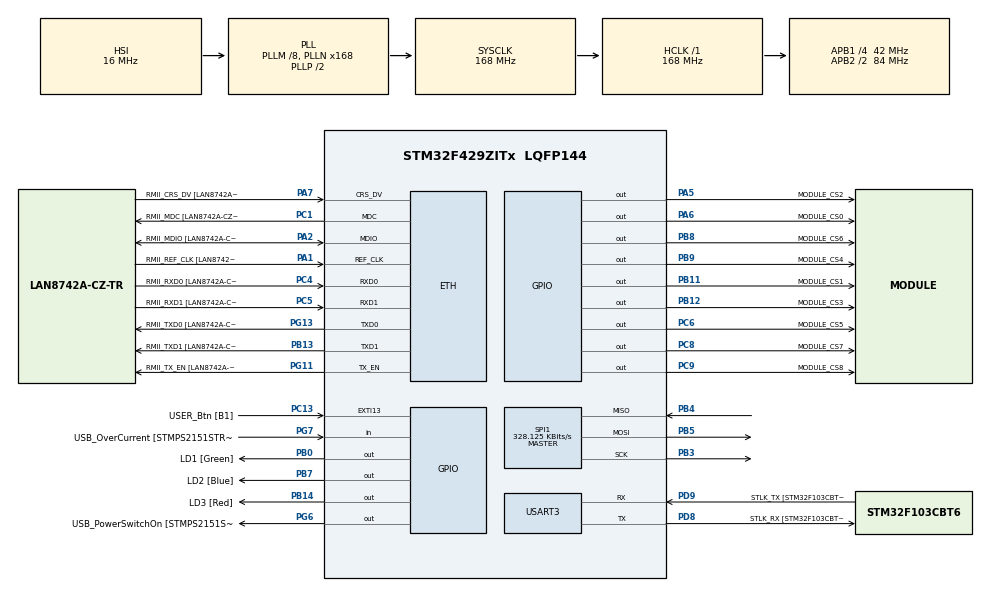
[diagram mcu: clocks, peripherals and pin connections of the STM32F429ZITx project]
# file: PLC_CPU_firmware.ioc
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Dma.Request0=SPI1_RX
Dma.Request1=SPI1_TX
Dma.SPI1_RX.0.Direction=DMA_PERIPH_TO_MEMORY
Dma.SPI1_RX.0.FIFOMode=DMA_FIFOMODE_DISABLE
Dma.SPI1_RX.0.Instance=DMA2_Stream0
Dma.SPI1_RX.0.MemDataAlignment=DMA_MDATAALIGN_BYTE
Dma.SPI1_RX.0.MemInc=DMA_MINC_ENABLE
Dma.SPI1_RX.0.Mode=DMA_NORMAL
Dma.SPI1_RX.0.PeriphDataAlignment=DMA_PDATAALIGN_BYTE
Dma.SPI1_RX.0.PeriphInc=DMA_PINC_DISABLE
Dma.SPI1_RX.0.Priority=DMA_PRIORITY_LOW
Dma.SPI1_TX.1.Direction=DMA_MEMORY_TO_PERIPH
Dma.SPI1_TX.1.FIFOMode=DMA_FIFOMODE_DISABLE
Dma.SPI1_TX.1.Instance=DMA2_Stream3
Dma.SPI1_TX.1.MemDataAlignment=DMA_MDATAALIGN_BYTE
Dma.SPI1_TX.1.MemInc=DMA_MINC_ENABLE
Dma.SPI1_TX.1.Mode=DMA_NORMAL
Dma.SPI1_TX.1.PeriphDataAlignment=DMA_PDATAALIGN_BYTE
Dma.SPI1_TX.1.PeriphInc=DMA_PINC_DISABLE
Dma.SPI1_TX.1.Priority=DMA_PRIORITY_LOW
ETH.MediaInterface=HAL_ETH_RMII_MODE
ETH.PHY_Name=LAN8742A_PHY_ADDRESS
ETH.PHY_Value=0
ETH.PhyAddress=0
FREERTOS.Events01=plc_status_flag,Static,plc_status_flagControlBlock
FREERTOS.Mutexes01=program_memory_write_mut,Static,program_memory_write_mut_cb
FREERTOS.Tasks01=DefaultTask,8,1024,DefaultTaskFcn,Default,NULL,Static,SystemInitTaskBuffer,SystemInitTaskControlBlock;TCPServerTask,16,1024,TCPServerTaskFcn,As weak,NULL,Static,TCPServerTaskBuffer,TCPServerTaskControlBlock;ModuleCtrlTask,55,1024,IoModuleControlTaskFcn,As external,NULL,Static,ModuleCtrlTaskBuffer,ModuleCtrlTaskControlBlock
FREERTOS.configCHECK_FOR_STACK_OVERFLOW=2
FREERTOS.configENABLE_FPU=0
FREERTOS.configMINIMAL_STACK_SIZE=1024
FREERTOS.configUSE_NEWLIB_REENTRANT=1
LWIP.BSP.number=1
LWIP.CHECKSUM_CHECK_IP=1
LWIP.CHECKSUM_CHECK_TCP=1
LWIP.CHECKSUM_GEN_IP=1
LWIP.CHECKSUM_GEN_TCP=1
LWIP.DEFAULT_THREAD_PRIO=46
LWIP.IP_ADDRESS=192.168.000.150
LWIP.LWIP_DHCP=0
LWIP.LWIP_NETIF_EXT_STATUS_CALLBACK=1
LWIP.LWIP_NETIF_STATUS_CALLBACK=1
LWIP.LWIP_STATS=0
LWIP.MEM_SIZE=16384
LWIP.NETMASK_ADDRESS=255.255.255.000
LWIP.TCPIP_THREAD_PRIO=47
LWIP.TCPIP_THREAD_STACKSIZE=2048
LWIP.Version=v2.1.2_Cube
LWIP0.BSP.STBoard=false
LWIP0.BSP.api=BSP_COMPONENT_DRIVER
LWIP0.BSP.component=LAN8742
LWIP0.BSP.instance=LAN8742
LWIP0.BSP.name=Driver_PHY
LWIP0.BSP.semaphore=S_LAN8742
LWIP0.BSP.solution=LAN8742
Mcu.Family=STM32F4
Mcu.Name=STM32F429ZITx
Mcu.Package=LQFP144
Mcu.UserConstants=hspi_module,$$_SPI1_IP_HANDLE_$$;htim_performance,$$_TIM5_IP_HANDLE_$$
NVIC.DMA2_Stream0_IRQn=true\:5\:0\:false\:false\:true\:true\:false\:true\:true
NVIC.DMA2_Stream3_IRQn=true\:5\:0\:false\:false\:true\:true\:false\:true\:true
NVIC.ETH_IRQn=true\:5\:0\:false\:false\:true\:true\:false\:true\:true
NVIC.PriorityGroup=NVIC_PRIORITYGROUP_4
NVIC.SPI1_IRQn=true\:5\:0\:false\:false\:true\:true\:true\:true\:true
NVIC.TIM7_IRQn=true\:15\:0\:false\:false\:true\:false\:false\:true\:true
NVIC.TimeBase=TIM7_IRQn
NVIC.TimeBaseIP=TIM7
PA1.GPIO_Label=RMII_REF_CLK [LAN8742A-CZ-TR_REFCLK0]
PA1.Mode=RMII
PA1.Signal=ETH_REF_CLK
PA10.GPIO_Label=USB_ID
PA10.Signal=USB_OTG_FS_ID
PA11.GPIO_Label=USB_DM
PA11.Signal=USB_OTG_FS_DM
PA12.GPIO_Label=USB_DP
PA12.Signal=USB_OTG_FS_DP
PA13.GPIO_Label=TMS
PA13.Mode=Serial_Wire
PA13.Signal=SYS_JTMS-SWDIO
PA14.GPIO_Label=TCK
PA14.Mode=Serial_Wire
PA14.Signal=SYS_JTCK-SWCLK
PA2.GPIO_Label=RMII_MDIO [LAN8742A-CZ-TR_MDIO]
PA2.Mode=RMII
PA2.Signal=ETH_MDIO
PA5.GPIO_Label=MODULE_CS2
PA5.Signal=GPIO_Output
PA6.GPIO_Label=MODULE_CS0
PA6.Signal=GPIO_Output
PA7.GPIO_Label=RMII_CRS_DV [LAN8742A-CZ-TR_CRS_DV]
PA7.Mode=RMII
PA7.Signal=ETH_CRS_DV
PA8.GPIO_Label=USB_SOF [TP1]
PA8.Signal=USB_OTG_FS_SOF
PA9.GPIO_Label=USB_VBUS
PA9.Signal=USB_OTG_FS_VBUS
PB0.GPIO_Label=LD1 [Green]
PB0.Signal=GPIO_Output
PB11.GPIO_Label=MODULE_CS1
PB11.Signal=GPIO_Output
PB12.GPIO_Label=MODULE_CS3
PB12.Signal=GPIO_Output
PB13.GPIO_Label=RMII_TXD1 [LAN8742A-CZ-TR_TXD1]
PB13.Mode=RMII
PB13.Signal=ETH_TXD1
PB14.GPIO_Label=LD3 [Red]
PB14.Signal=GPIO_Output
PB3.Mode=Full_Duplex_Master
PB3.Signal=SPI1_SCK
PB4.GPIO_PuPd=GPIO_PULLDOWN
PB4.Mode=Full_Duplex_Master
PB4.Signal=SPI1_MISO
PB5.Mode=Full_Duplex_Master
PB5.Signal=SPI1_MOSI
PB7.GPIO_Label=LD2 [Blue]
PB7.Signal=GPIO_Output
PB8.GPIO_Label=MODULE_CS6
PB8.Signal=GPIO_Output
PB9.GPIO_Label=MODULE_CS4
PB9.Signal=GPIO_Output
PC1.GPIO_Label=RMII_MDC [LAN8742A-CZ-TR_MDC]
PC1.Mode=RMII
PC1.Signal=ETH_MDC
PC13.GPIO_Label=USER_Btn [B1]
PC13.Signal=GPXTI13
PC14/OSC32_IN.Mode=LSE-External-Oscillator
PC14/OSC32_IN.Signal=RCC_OSC32_IN
PC15/OSC32_OUT.Mode=LSE-External-Oscillator
PC15/OSC32_OUT.Signal=RCC_OSC32_OUT
PC4.GPIO_Label=RMII_RXD0 [LAN8742A-CZ-TR_RXD0]
PC4.Mode=RMII
PC4.Signal=ETH_RXD0
PC5.GPIO_Label=RMII_RXD1 [LAN8742A-CZ-TR_RXD1]
PC5.Mode=RMII
PC5.Signal=ETH_RXD1
PC6.GPIO_Label=MODULE_CS5
PC6.Signal=GPIO_Output
PC8.GPIO_Label=MODULE_CS7
PC8.Signal=GPIO_Output
PC9.GPIO_Label=MODULE_CS8
PC9.Signal=GPIO_Output
PD8.GPIO_Label=STLK_RX [STM32F103CBT6_PA3]
PD8.Mode=Asynchronous
PD8.Signal=USART3_TX
PD9.GPIO_Label=STLK_TX [STM32F103CBT6_PA2]
PD9.Mode=Asynchronous
PD9.Signal=USART3_RX
PG11.GPIO_Label=RMII_TX_EN [LAN8742A-CZ-TR_TXEN]
PG11.Mode=RMII
PG11.Signal=ETH_TX_EN
PG13.GPIO_Label=RMII_TXD0 [LAN8742A-CZ-TR_TXD0]
PG13.Mode=RMII
PG13.Signal=ETH_TXD0
PG6.GPIO_Label=USB_PowerSwitchOn [STMPS2151STR_EN]
PG6.Signal=GPIO_Output
PG7.GPIO_Label=USB_OverCurrent [STMPS2151STR_FAULT]
PG7.Signal=GPIO_Input
PH0/OSC_IN.GPIO_Label=MCO [STM32F103CBT6_PA8]
PH0/OSC_IN.Mode=HSE-External-Clock-Source
PH0/OSC_IN.Signal=RCC_OSC_IN
PH1/OSC_OUT.Mode=HSE-External-Clock-Source
PH1/OSC_OUT.Signal=RCC_OSC_OUT
ProjectManager.HeapSize=0x200
ProjectManager.StackSize=0x400
ProjectManager.TargetToolchain=STM32CubeIDE
RCC.48MHZClocksFreq_Value=48000000
RCC.AHBFreq_Value=168000000
RCC.APB1CLKDivider=RCC_HCLK_DIV4
RCC.APB1Freq_Value=42000000
RCC.APB1TimFreq_Value=84000000
RCC.APB2CLKDivider=RCC_HCLK_DIV2
RCC.APB2Freq_Value=84000000
RCC.APB2TimFreq_Value=168000000
RCC.CortexFreq_Value=168000000
RCC.HCLKFreq_Value=168000000
RCC.HSE_VALUE=8000000
RCC.HSI_VALUE=16000000
RCC.PLLM=8
RCC.PLLMUL=RCC_PLL_MUL9
RCC.PLLN=168
RCC.PLLQ=7
RCC.PRESCALERUSB=RCC_USBCLKSOURCE_PLL_DIV1_5
RCC.SYSCLKFreq_VALUE=168000000
RCC.SYSCLKSource=RCC_SYSCLKSOURCE_PLLCLK
RCC.SYSCLKSourceVirtual=RCC_SYSCLKSOURCE_PLLCLK
RCC.USBFreq_Value=48000000
RCC.VCOOutputFreq_Value=336000000
SPI1.BaudRatePrescaler=SPI_BAUDRATEPRESCALER_256
SPI1.CalculateBaudRate=328.125 KBits/s
SPI1.Direction=SPI_DIRECTION_2LINES
SPI1.Mode=SPI_MODE_MASTER
SPI1.VirtualType=VM_MASTER
USART3.VirtualMode=VM_ASYNC
VP_CRC_VS_CRC.Mode=CRC_Activate
VP_FREERTOS_VS_CMSIS_V2.Mode=CMSIS_V2
VP_LWIP_VS_Enabled.Mode=Enabled
VP_SYS_VS_tim7.Mode=TIM7
VP_TIM5_VS_ClockSourceINT.Mode=Internal
board=NUCLEO-F429ZI

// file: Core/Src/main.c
/* USER CODE BEGIN Header */
/**
  ******************************************************************************
  * @file           : main.c
  * @brief          : Main program body
  ******************************************************************************
  * @attention
  *
  * Copyright (c) 2024 STMicroelectronics.
  * All rights reserved.
  *
  * This software is licensed under terms that can be found in the LICENSE file
  * in the root directory of this software component.
  * If no LICENSE file comes with this software, it is provided AS-IS.
  *
  ******************************************************************************
  */
/* USER CODE END Header */
#include "main.h"
#include "cmsis_os.h"
#include "crc.h"
#include "dma.h"
#include "lwip.h"
#include "spi.h"
#include "tim.h"
#include "usart.h"
#include "gpio.h"

void SystemClock_Config(void);
void MX_FREERTOS_Init(void);

int main(void)
{

  /* MCU Configuration--------------------------------------------------------*/

  /* Reset of all peripherals, Initializes the Flash interface and the Systick. */
  HAL_Init();

  /* Configure the system clock */
  SystemClock_Config();

  /* USER CODE BEGIN SysInit */
  HAL_Delay(100);

  /* USER CODE END SysInit */

  /* Initialize all configured peripherals */
  MX_GPIO_Init();
  MX_DMA_Init();
  MX_USART3_UART_Init();
  MX_SPI1_Init();
  MX_CRC_Init();
  MX_TIM5_Init();

  /* Init scheduler */
  osKernelInitialize();  /* Call init function for freertos objects (in freertos.c) */
  MX_FREERTOS_Init();

  /* Start scheduler */
  osKernelStart();
  /* We should never get here as control is now taken by the scheduler */
  /* Infinite loop */
  while (1)
  {

  }
}

void SystemClock_Config(void)
{
  RCC_OscInitTypeDef RCC_OscInitStruct = {0};
  RCC_ClkInitTypeDef RCC_ClkInitStruct = {0};

  /** Configure the main internal regulator output voltage
  */
  __HAL_RCC_PWR_CLK_ENABLE();
  __HAL_PWR_VOLTAGESCALING_CONFIG(PWR_REGULATOR_VOLTAGE_SCALE1);

  /** Initializes the RCC Oscillators according to the specified parameters
  * in the RCC_OscInitTypeDef structure.
  */
  RCC_OscInitStruct.OscillatorType = RCC_OSCILLATORTYPE_HSI;
  RCC_OscInitStruct.HSIState = RCC_HSI_ON;
  RCC_OscInitStruct.HSICalibrationValue = RCC_HSICALIBRATION_DEFAULT;
  RCC_OscInitStruct.PLL.PLLState = RCC_PLL_ON;
  RCC_OscInitStruct.PLL.PLLSource = RCC_PLLSOURCE_HSI;
  RCC_OscInitStruct.PLL.PLLM = 8;
  RCC_OscInitStruct.PLL.PLLN = 168;
  RCC_OscInitStruct.PLL.PLLP = RCC_PLLP_DIV2;
  RCC_OscInitStruct.PLL.PLLQ = 7;
  if (HAL_RCC_OscConfig(&RCC_OscInitStruct) != HAL_OK)
  {
    Error_Handler();
  }

  /** Initializes the CPU, AHB and APB buses clocks
  */
  RCC_ClkInitStruct.ClockType = RCC_CLOCKTYPE_HCLK|RCC_CLOCKTYPE_SYSCLK
                              |RCC_CLOCKTYPE_PCLK1|RCC_CLOCKTYPE_PCLK2;
  RCC_ClkInitStruct.SYSCLKSource = RCC_SYSCLKSOURCE_PLLCLK;
  RCC_ClkInitStruct.AHBCLKDivider = RCC_SYSCLK_DIV1;
  RCC_ClkInitStruct.APB1CLKDivider = RCC_HCLK_DIV4;
  RCC_ClkInitStruct.APB2CLKDivider = RCC_HCLK_DIV2;

  if (HAL_RCC_ClockConfig(&RCC_ClkInitStruct, FLASH_LATENCY_5) != HAL_OK)
  {
    Error_Handler();
  }
}

void HAL_TIM_PeriodElapsedCallback(TIM_HandleTypeDef *htim)
{
  if (htim->Instance == TIM7) {
    HAL_IncTick();
  }
}

void Error_Handler(void)
{
  __disable_irq();
  while (1)
  {
  }
}

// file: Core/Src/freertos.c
/* USER CODE BEGIN Header */
/**
  ******************************************************************************
  * File Name          : freertos.c
  * Description        : Code for freertos applications
  ******************************************************************************
  * @attention
  *
  * Copyright (c) 2024 STMicroelectronics.
  * All rights reserved.
  *
  * This software is licensed under terms that can be found in the LICENSE file
  * in the root directory of this software component.
  * If no LICENSE file comes with this software, it is provided AS-IS.
  *
  ******************************************************************************
  */
/* USER CODE END Header */

#include "FreeRTOS.h"
#include "task.h"
#include "main.h"
#include "cmsis_os.h"

typedef StaticTask_t osStaticThreadDef_t;
typedef StaticSemaphore_t osStaticMutexDef_t;
typedef StaticEventGroup_t osStaticEventGroupDef_t;

/* Definitions for DefaultTask */
osThreadId_t DefaultTaskHandle;
uint32_t SystemInitTaskBuffer[ 1024 ];
osStaticThreadDef_t SystemInitTaskControlBlock;
const osThreadAttr_t DefaultTask_attributes = {
  .name = "DefaultTask",
  .cb_mem = &SystemInitTaskControlBlock,
  .cb_size = sizeof(SystemInitTaskControlBlock),
  .stack_mem = &SystemInitTaskBuffer[0],
  .stack_size = sizeof(SystemInitTaskBuffer),
  .priority = (osPriority_t) osPriorityLow,
};
/* Definitions for TCPServerTask */
osThreadId_t TCPServerTaskHandle;
uint32_t TCPServerTaskBuffer[ 1024 ];
osStaticThreadDef_t TCPServerTaskControlBlock;
const osThreadAttr_t TCPServerTask_attributes = {
  .name = "TCPServerTask",
  .cb_mem = &TCPServerTaskControlBlock,
  .cb_size = sizeof(TCPServerTaskControlBlock),
  .stack_mem = &TCPServerTaskBuffer[0],
  .stack_size = sizeof(TCPServerTaskBuffer),
  .priority = (osPriority_t) osPriorityBelowNormal,
};
/* Definitions for ModuleCtrlTask */
osThreadId_t ModuleCtrlTaskHandle;
uint32_t ModuleCtrlTaskBuffer[ 1024 ];
osStaticThreadDef_t ModuleCtrlTaskControlBlock;
const osThreadAttr_t ModuleCtrlTask_attributes = {
  .name = "ModuleCtrlTask",
  .cb_mem = &ModuleCtrlTaskControlBlock,
  .cb_size = sizeof(ModuleCtrlTaskControlBlock),
  .stack_mem = &ModuleCtrlTaskBuffer[0],
  .stack_size = sizeof(ModuleCtrlTaskBuffer),
  .priority = (osPriority_t) osPriorityRealtime7,
};
/* Definitions for program_memory_write_mut */
osMutexId_t program_memory_write_mutHandle;
osStaticMutexDef_t program_memory_write_mut_cb;
const osMutexAttr_t program_memory_write_mut_attributes = {
  .name = "program_memory_write_mut",
  .cb_mem = &program_memory_write_mut_cb,
  .cb_size = sizeof(program_memory_write_mut_cb),
};
/* Definitions for plc_status_flag */
osEventFlagsId_t plc_status_flagHandle;
osStaticEventGroupDef_t plc_status_flagControlBlock;
const osEventFlagsAttr_t plc_status_flag_attributes = {
  .name = "plc_status_flag",
  .cb_mem = &plc_status_flagControlBlock,
  .cb_size = sizeof(plc_status_flagControlBlock),
};

void DefaultTaskFcn(void *argument);
void TCPServerTaskFcn(void *argument);
extern void IoModuleControlTaskFcn(void *argument);

extern void MX_LWIP_Init(void);
void MX_FREERTOS_Init(void); /* (MISRA C 2004 rule 8.1) */

/* Hook prototypes */
void vApplicationStackOverflowHook(xTaskHandle xTask, signed char *pcTaskName);

/* USER CODE BEGIN 4 */

int overflow = 0;
signed char *overflow_pcTaskName = 0;
xTaskHandle overflow_xTask;

void vApplicationStackOverflowHook(xTaskHandle xTask, signed char *pcTaskName)
{
   /* Run time stack overflow checking is performed if
   configCHECK_FOR_STACK_OVERFLOW is defined to 1 or 2. This hook function is
   called if a stack overflow is detected. */
	overflow = 1;
	overflow_pcTaskName = pcTaskName;
	overflow_xTask = xTask;
}
/* USER CODE END 4 */

void MX_FREERTOS_Init(void) {
  /* Create the mutex(es) */
  /* creation of program_memory_write_mut */
  program_memory_write_mutHandle = osMutexNew(&program_memory_write_mut_attributes);

  /* Create the thread(s) */
  /* creation of DefaultTask */
  DefaultTaskHandle = osThreadNew(DefaultTaskFcn, NULL, &DefaultTask_attributes);

  /* creation of TCPServerTask */
  TCPServerTaskHandle = osThreadNew(TCPServerTaskFcn, NULL, &TCPServerTask_attributes);

  /* creation of ModuleCtrlTask */
  ModuleCtrlTaskHandle = osThreadNew(IoModuleControlTaskFcn, NULL, &ModuleCtrlTask_attributes);

  /* creation of plc_status_flag */
  plc_status_flagHandle = osEventFlagsNew(&plc_status_flag_attributes);

}

void DefaultTaskFcn(void *argument)
{
  /* init code for LWIP */
  MX_LWIP_Init();
  for(;;)
  {
    osDelay(1);
  }
}

__weak void TCPServerTaskFcn(void *argument)
{
  for(;;)
  {
    osDelay(1);
  }
}
